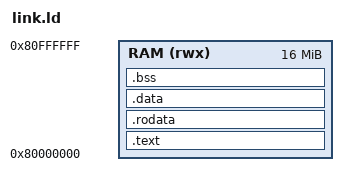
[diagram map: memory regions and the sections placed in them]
OUTPUT_ARCH(riscv)
ENTRY(_start)

MEMORY {
  RAM (rwx) : ORIGIN = 0x80000000, LENGTH = 16M
}

SECTIONS {
  .text : {
    *(.text.entry)
    *(.text*)
  } > RAM

  .rodata : { *(.rodata*) } > RAM
  .data   : { *(.data*) } > RAM
  .bss    : {
    __bss_start = .;
    *(.bss*)
    *(COMMON)
    __bss_end = .;
  } > RAM

  . = ALIGN(16);
  . = . + 0x4000; /* 16KB stack */
  __stack_top = .;
}
